AUTOSAR XML (schema 4-0-3)
package /ComponentTypes
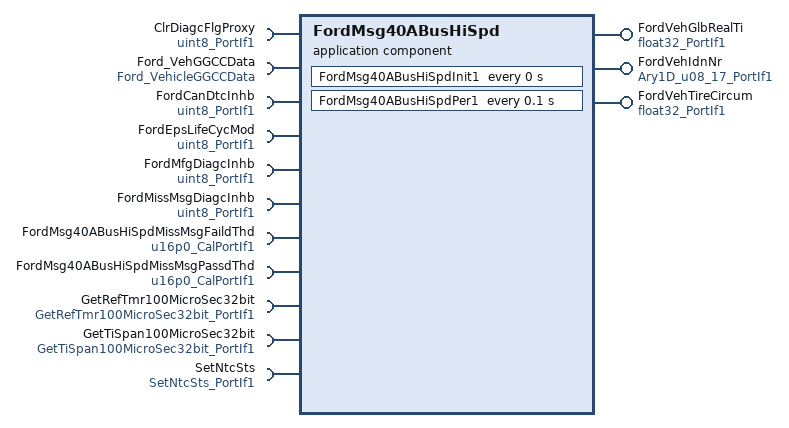
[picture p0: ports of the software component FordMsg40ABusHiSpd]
  application sw component type FordMsg40ABusHiSpd
    provide port FordVehGlbRealTi: nonqueued-sender-com-spec{data-element=Val, init-value=0.1}, provided-interface=float32_PortIf1
    provide port FordVehIdnNr: nonqueued-sender-com-spec{data-element=Ary1D, init-value=17 x 0}, provided-interface=Ary1D_u08_17_PortIf1
    provide port FordVehTireCircum: nonqueued-sender-com-spec{data-element=Val, init-value=65534}, provided-interface=float32_PortIf1
    11 x require port:
      ClrDiagcFlgProxy: nonqueued-receiver-com-spec{data-element=Val, filter=data-filter-type=ALWAYS, init-value=0}, required-interface=uint8_PortIf1
      Ford_VehGGCCData: nonqueued-receiver-com-spec{data-element=Ford_VehicleGGCCData, filter=data-filter-type=ALWAYS, init-value=8 x 0}, required-interface=Ford_VehicleGGCCData
      FordCanDtcInhb: nonqueued-receiver-com-spec{data-element=Val, filter=data-filter-type=ALWAYS, init-value=1}, required-interface=uint8_PortIf1
      FordEpsLifeCycMod: nonqueued-receiver-com-spec{data-element=Val, filter=data-filter-type=ALWAYS, init-value=0}, required-interface=uint8_PortIf1
      FordMfgDiagcInhb: nonqueued-receiver-com-spec{data-element=Val, filter=data-filter-type=ALWAYS, init-value=0}, required-interface=uint8_PortIf1
      FordMissMsgDiagcInhb: nonqueued-receiver-com-spec{data-element=Val, filter=data-filter-type=ALWAYS, init-value=0}, required-interface=uint8_PortIf1
      FordMsg40ABusHiSpdMissMsgFaildThd: parameter-require-com-spec{init-value=5000, parameter=Val}, required-interface=u16p0_CalPortIf1
      FordMsg40ABusHiSpdMissMsgPassdThd: parameter-require-com-spec{init-value=0, parameter=Val}, required-interface=u16p0_CalPortIf1
      GetRefTmr100MicroSec32bit: client-com-spec=Oper, required-interface=GetRefTmr100MicroSec32bit_PortIf1
      GetTiSpan100MicroSec32bit: client-com-spec=Oper, required-interface=GetTiSpan100MicroSec32bit_PortIf1
      SetNtcSts: client-com-spec=Oper, required-interface=SetNtcSts_PortIf1
    behavior FordMsg40ABusHiSpd_InternalBehavior
      ar-typed-per-instance-memorys:
        11 x data, all with sw-calibration-access=READ-ONLY:
          FordClrDiagcFlgProxyPrev: type=uint8
          FordVehGlbRealTiPrev: type=float32
          FordVehIdnNrC100Prev: type=Ary1D_u08_6
          FordVehIdnNrC101Prev: type=Ary1D_u08_6
          FordVehIdnNrC102Prev: type=Ary1D_u08_5
          FordVehIdnNrPrev: type=Ary1D_u08_17
          FordVehMsg40AMiss: type=boolean
          FordVehMsg40ARxd: type=boolean
          FordVehTireCircumPrev: type=float32
          MissMsgFaildRefTi: type=uint32
          MissMsgPassdRefTi: type=uint32
      timing event FordMsg40ABusHiSpd_InitEvent: start-on-event=FordMsg40ABusHiSpdInit1, period=0
      timing event TMT_FordMsg40ABusHiSpdPer1: start-on-event=FordMsg40ABusHiSpdPer1, period=0.1
      port-api-options:
        enable-take-address=false, indirect-api=false, port=ClrDiagcFlgProxy
        enable-take-address=false, indirect-api=false, port=Ford_VehGGCCData
      runnable FordMsg40ABusHiSpdInit1
        sync call SC_GetRefTmr100MicroSec32bit_Oper: operation=GetRefTmr100MicroSec32bit.Oper, timeout=0
      runnable FordMsg40ABusHiSpdPer1
        data-receive-point-by-arguments:
          6 x access:
            REC_ClrDiagcFlgProxy_Val: accessed-variable=ClrDiagcFlgProxy.Val
            REC_Ford_VehGGCCData_Ford_VehicleGGCCData: accessed-variable=Ford_VehGGCCData.Ford_VehicleGGCCData
            REC_FordCanDtcInhb_Val: accessed-variable=FordCanDtcInhb.Val
            REC_FordEpsLifeCycMod_Val: accessed-variable=FordEpsLifeCycMod.Val
            REC_FordMfgDiagcInhb_Val: accessed-variable=FordMfgDiagcInhb.Val
            REC_FordMissMsgDiagcInhb_Val: accessed-variable=FordMissMsgDiagcInhb.Val
        data-send-points:
          access SEND_FordVehGlbRealTi_Val: accessed-variable=FordVehGlbRealTi.Val
          access SEND_FordVehIdnNr_Ary1D: accessed-variable=FordVehIdnNr.Ary1D
          access SEND_FordVehTireCircum_Val: accessed-variable=FordVehTireCircum.Val
        sync call SC_GetRefTmr100MicroSec32bit_Oper: operation=GetRefTmr100MicroSec32bit.Oper, timeout=0
        sync call SC_GetTiSpan100MicroSec32bit_Oper: operation=GetTiSpan100MicroSec32bit.Oper, timeout=0
        sync call SC_SetNtcSts_Oper: operation=SetNtcSts.Oper, timeout=0
  swc implementation FordMsg40ABusHiSpd_Implementation: behavior=FordMsg40ABusHiSpd_InternalBehavior
    code-descriptors:
      code Default: artifact-descriptors=autosar-engineering-object={short-label=Default, category=SWSRC}
